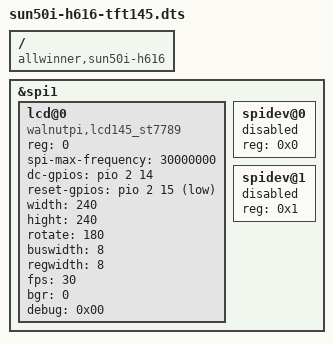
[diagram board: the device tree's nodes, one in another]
/dts-v1/;
/plugin/;

/ {
	compatible = "allwinner,sun50i-h616";

	fragment@0 {
		target = <&spi1>;
		 __overlay__ {
			#address-cells = <1>;
   			#size-cells = <0>;
			status = "okay";
			lcd@0{
				compatible = "walnutpi,lcd145_st7789";
				reg = <0>;
				spi-max-frequency = <30000000>;
				status = "okay";

				dc-gpios = <&pio  2 14 0>; /* PC14  GPIO_ACTIVE_HIGH*/
				reset-gpios = <&pio 2 15 1>; /* PC15  GPIO_ACTIVE_LOW */
				width = <240>;
				hight = <240>;
				rotate = <180>;
				buswidth = <8>;
				regwidth = <8>;
				fps = <30>;
				bgr = <0> ;
				debug = <0x00>;
			};
			


		};
	};
	
	fragment@1 {
		target = <&spi1>;
		__overlay__ {
			status = "okay";
			#address-cells = <1>;
			#size-cells = <0>;

			spidev@0 {
				status = "disabled";
				reg = <0x0>;
			};

			spidev@1 {
				status = "disabled";
				reg = <0x1>;
			};
		};
	};

};
